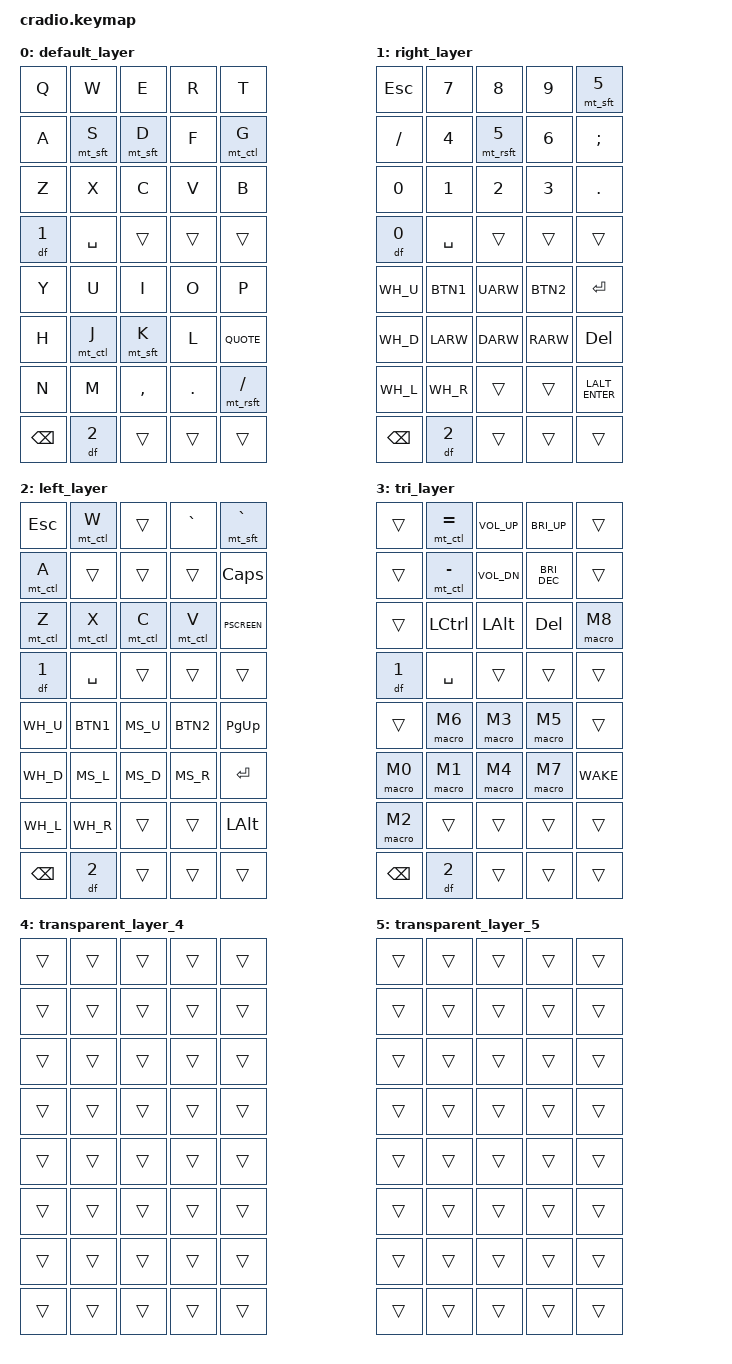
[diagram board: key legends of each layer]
// Copyright (c) 2022–2026 The ZMK Contributors
// SPDX-License-Identifier: MIT

#include <behaviors.dtsi>
#include <dt-bindings/zmk/keys.h>
#include <dt-bindings/zmk/bt.h>
#include <dt-bindings/zmk/outputs.h>

// Home row mod macros (unchanged)
#define HRML(k2,k3,k4) &ht LALT k2  &ht LCTRL k3  &ht LGUI k4
#define HRMR(k1,k2,k3) &ht RGUI k1  &ht RCTRL k2  &ht RALT k3
#define WHRML(k2,k3,k4) &ht LALT k2  &ht LGUI k3  &ht LCTRL k4
#define WHRMR(k1,k2,k3) &ht RCTRL k1  &ht RGUI k2  &ht RALT k3

#define MAC 0
#define WIN 1
#define RIG 2
#define LEF 3
#define TRI 4

/ {
    behaviors {

        // General home-row-mod hold-tap
        ht: hold_tap {
            label = "hold_tap";
            compatible = "zmk,behavior-hold-tap";
            #binding-cells = <2>;
            flavor = "tap-preferred";
            tapping-term-ms = <220>;
            quick-tap-ms = <150>;
            global-quick-tap;
            bindings = <&kp>, <&kp>;
        };

        // LCTL_T, LSFT_T, RSFT_T, RALT_T etc.
        mt_ctl: mt_LCTL {
            label = "LCTL_TAP";
            compatible = "zmk,behavior-hold-tap";
            #binding-cells = <2>;
            flavor = "tap-preferred";
            tapping-term-ms = <200>;
            bindings = <&kp>, <&kp LCTRL>;
        };

        mt_sft: mt_LSFT {
            label = "LSFT_TAP";
            compatible = "zmk,behavior-hold-tap";
            #binding-cells = <2>;
            flavor = "tap-preferred";
            tapping-term-ms = <200>;
            bindings = <&kp>, <&kp LSHIFT>;
        };

        mt_rsft: mt_RSFT {
            label = "RSFT_TAP";
            compatible = "zmk,behavior-hold-tap";
            #binding-cells = <2>;
            flavor = "tap-preferred";
            tapping-term-ms = <200>;
            bindings = <&kp>, <&kp RSHIFT>;
        };

        mt_ralt: mt_RALT {
            label = "RALT_TAP";
            compatible = "zmk,behavior-hold-tap";
            #binding-cells = <2>;
            flavor = "tap-preferred";
            tapping-term-ms = <200>;
            bindings = <&kp>, <&kp RALT>;
        };

        // DF layers: DF(0), DF(1), DF(2), DF(3)
        df: df_layer {
            compatible = "zmk,behavior-layer";
            #binding-cells = <1>;
            label = "DF_LAYER";
        };
    };

    conditional_layers {
        compatible = "zmk,conditional-layers";

        tri_layer {
            if-layers = <RIG LEF>;
            then-layer = <TRI>;
        };
    };

    keymap {
        compatible = "zmk,keymap";

        // === Layer 0: Default typing (QMK layer 0) ===
        default_layer {
            bindings = <
                // Left half – top row
                &kp Q      &kp W      &kp E      &kp R      &kp T
                // Left row 2 – home row + LCTL_T(G)
                &kp A      &mt_sft S   &mt_sft D   &kp F      &mt_ctl G
                // Left row 3 – bottom row
                &kp Z      &kp X      &kp C      &kp V      &kp B
                // Left thumb
                &df 1       &kp SPACE  &trans     &trans     &trans

                // Right half – top row
                &kp Y      &kp U      &kp I      &kp O      &kp P
                // Right row 2 – LCTL_T(J), LSFT_T(K), RALT quote
                &kp H      &mt_ctl J  &mt_sft K  &kp L      &kp QUOTE
                // Right row 3 – bottom row
                &kp N      &kp M      &kp COMMA  &kp DOT    &mt_rsft SLASH
                // Right thumb
                &kp BSPC   &df 2       &trans     &trans     &trans
            >;
        };

        // === Layer 1: Navigation / wheel / mouse (QMK layer 1) ===
        right_layer {
            bindings = <
                // Left side – 7 8 9 + ESC / 0 1 2 3 4
                &kp ESC    &kp N7     &kp N8     &kp N9     &mt_sft N5
                &kp FSLH   &kp N4     &mt_rsft N5 &kp N6     &kp SEMI
                &kp N0     &kp N1     &kp N2     &kp N3     &kp DOT
                &df 0       &kp SPACE  &trans     &trans     &trans

                // Right side – thumb cluster + wheel + nav
                &kp WH_U   &kp BTN1   &kp UARW   &kp BTN2   &kp ENTER
                &kp WH_D   &kp LARW   &kp DARW   &kp RARW   &kp DEL
                &kp WH_L   &kp WH_R   &trans     &trans     &kp LALT_ENTER
                &kp BSPC   &df 2       &trans     &trans     &trans
            >;
        };

        // === Layer 2: System / caps / mouse movement (QMK layer 2) ===
        left_layer {
            bindings = <
                // Left side – RCTL(W), LCTL(A), LCTL(Z) shortcuts, caps
                &kp ESC    &mt_ctl W   &trans      &kp GRAVE   &mt_sft GRAVE
                &mt_ctl A   &trans      &trans      &trans      &kp CAPSLOCK
                &mt_ctl Z   &mt_ctl X   &mt_ctl C   &mt_ctl V   &kp PSCREEN
                &df 1       &kp SPACE  &trans     &trans     &trans

                // Right side – mouse wheel + pointer + page keys
                &kp WH_U   &kp BTN1   &kp MS_U   &kp BTN2   &kp PG_UP
                &kp WH_D   &kp MS_L   &kp MS_D   &kp MS_R   &kp ENTER
                &kp WH_L   &kp WH_R   &trans     &trans     &kp LALT
                &kp BSPC   &df 2       &trans     &trans     &trans
            >;
        };

        // === Layer 3: Audio / brightness / macros (QMK layer 3) ===
        tri_layer {
            bindings = <
                // Left side – audio + brightness + LCTRL / LALT + DEL + M8
                &trans    &mt_ctl EQUAL &kp C_VOL_UP  &kp C_BRI_UP  &trans
                &trans    &mt_ctl MINUS &kp C_VOL_DN  &kp C_BRI_DEC &trans
                &trans    &kp LCTRL    &kp LALT      &kp DEL       &macro M8
                &df 1       &kp SPACE  &trans       &trans       &trans

                // Right side – M0–M7 + WAKE
                &trans    &macro M6   &macro M3   &macro M5   &trans
                &macro M0  &macro M1   &macro M4   &macro M7   &kp WAKE
                &macro M2  &trans      &trans      &trans      &trans
                &kp BSPC   &df 2       &trans     &trans     &trans
            >;
        };

        // === Layer 4 / 5: Transparent (QMK layers 4–5) ===
        transparent_layer_4 {
            bindings = <
                &trans &trans &trans &trans &trans
                &trans &trans &trans &trans &trans
                &trans &trans &trans &trans &trans
                &trans &trans &trans &trans &trans
                &trans &trans &trans &trans &trans
                &trans &trans &trans &trans &trans
                &trans &trans &trans &trans &trans
                &trans &trans &trans &trans &trans
            >;
        };

        transparent_layer_5 {
            bindings = <
                &trans &trans &trans &trans &trans
                &trans &trans &trans &trans &trans
                &trans &trans &trans &trans &trans
                &trans &trans &trans &trans &trans
                &trans &trans &trans &trans &trans
                &trans &trans &trans &trans &trans
                &trans &trans &trans &trans &trans
                &trans &trans &trans &trans &trans
            >;
        };
    };

    // === Macros (from your QMK `macro` array) ===
    macros {
        // M0: HKJC Entries link
        M0: macro_0 {
            compatible = "zmk,behavior-macro";
            labels = "HKJC_ENTRIES";
            #macro-cells = <0>;
            bindings = <&macro_text "https://racing.hkjc.com/racing/information/Chinese/racing/Entries.aspx">, &kp ENTER>;
        };

        // M1: HKJC Racecard link
        M1: macro_1 {
            compatible = "zmk,behavior-macro";
            labels = "HKJC_RACECARD";
            #macro-cells = <0>;
            bindings = <&macro_text "https://racing.hkjc.com/racing/information/Chinese/racing/Racecard.aspx">, &kp ENTER>;
        };

        // M2: SQL snippet
        M2: macro_2 {
            compatible = "zmk,behavior-macro";
            labels = "SQL_COUNT";
            #macro-cells = <0>;
            bindings = <&macro_text "SELECT COUNT(*) FROM ">;
        };

        // M3: QCCRMM URL
        M3: macro_3 {
            compatible = "zmk,behavior-macro";
            labels = "QCCRMM_URL";
            #macro-cells = <0>;
            bindings = <&macro_text "https://qccrmm.corpqc.hkjc.com">>;
        };

        // M4: CRM URL
        M4: macro_4 {
            compatible = "zmk,behavior-macro";
            labels = "CRM_URL";
            #macro-cells = <0>;
            bindings = <&macro_text "https://crm.corpqc.hkjc.com/sat01/main.aspx#">>;
        };

        // M5: Bragt01 login macro
        M5: macro_5 {
            compatible = "zmk,behavior-macro";
            labels = "BRAGT01_LOGIN";
            #macro-cells = <0>;
            bindings =
                <&macro_text "Bragt01">, &kp TAB, &macro_text "0000abc!">, &kp ENTER>;
        };

        // M6: Brsup01 login macro
        M6: macro_6 {
            compatible = "zmk,behavior-macro";
            labels = "BRSUP01_LOGIN";
            #macro-cells = <0>;
            bindings =
                <&macro_text "Brsup01">, &kp TAB, &macro_text "0000abc!">, &kp ENTER>;
        };

        // M7: testbed_dm\\crmtest03 login macro
        M7: macro_7 {
            compatible = "zmk,behavior-macro";
            labels = "CRMTEST_LOGIN";
            #macro-cells = <0>;
            bindings =
                <&macro_text "testbed_dm\\\\\\\\crmtest03">, &kp TAB, &macro_text "0000abc!">, &kp ENTER>;
        };

        // M8: password macro (just typing the password)
        M8: macro_8 {
            compatible = "zmk,behavior-macro";
            labels = "PASSWORD_ROMANTIC";
            #macro-cells = <0>;
            bindings =
                <&macro_text "R0mAnT1CWArriOr82">, &kp ENTER>;
        };
    };
};
